# EG32M0x register map
Vendor: EGmicro Ltd.; Series: EG32M0x; File version: 1.0
CPU: CM0 r0p0, little endian, no MPU, no FPU, 3 interrupt priority bits
Registers are 32-bit, read-write, reset 0x0 unless marked. A register's access mark holds for its fields unless they carry their own. Offsets are from the block's base; [hi:lo] are bit positions; {n}, {i} and the like mark numbered series.

## HWDIV — HWDIV unit
Base 0x400203A0
0x00 DR
  [31:0] DIVDR — Dividend data
0x04 SR
  [31:0] DIVSR — Divisor data
0x08 QUO
  [31:0] DIVQUO — Quotient result
0x0C REM
  [31:0] DIVREM — Remainder result
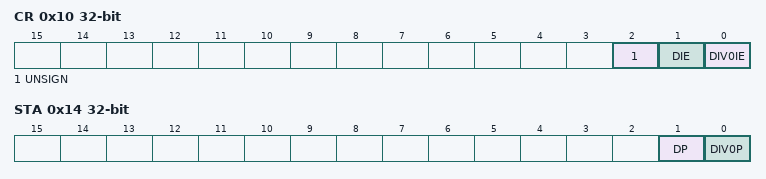
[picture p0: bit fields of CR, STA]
0x10 CR
  [2] UNSIGN — Operation symbol bit control
  [1] DIE — End of operation interrupt control bit
  [0] DIV0IE — Divisor is 0 interrupt control bit
0x14 STA
  [1] DP — End of operation flag bit
  [0] DIV0P — The divisor is 0

## POWER_MAN — POWER MANAGEMENT unit
Base 0x40020120
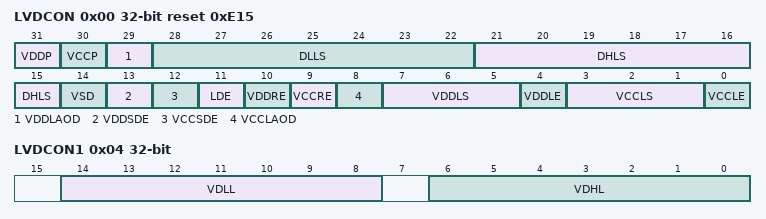
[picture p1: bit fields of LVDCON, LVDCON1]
0x00 LVDCON reset 0xE15
  [31] VDDP — When the VDD voltage is lower than the threshold, the PEND is triggered
  [30] VCCP — When the VCC voltage is lower than the threshold, the PEND is triggered
  [29] VDDLAOD — VDD_LVD Analog signal output is enabled
  [28:22] DLLS — Low level burr filter width for PMU_LVD_VDD signal The degree of
  [21:15] DHLS — High level burr filter width for PMU_LVD_VDD signal The degree of
  [14] VSD — VCC_LVD Indicates whether to wake up the CPU in interrupt mode The system clock must be synchronized first
  [13] VDDSDE — Mask the filtering processing of PMU_VDD_LVD signal
  [12] VCCSDE — Mask the filtering processing of PMU_VCC_LVD signal
  [11] LDE — LVD digital switch
  [10] VDDRE — The system reset function is enabled after the VDD threshold is triggered
  [9] VCCRE — The system reset function is enabled after the VCC threshold is triggered
  [8] VCCLAOD — VCC_LVD Analog signal output is enabled
  [7:5] VDDLS — VDD_LVD Voltage detection Setting
  [4] VDDLE — VDD_LVD analog switch
  [3:1] VCCLS — VCC_LVD Voltage detection Setting
  [0] VCCLE — VCC_LVD analog switch
0x04 LVDCON1
  [14:8] VDLL — Low level burr filter width for PMU_LVD_VCC signal The degree of
  [6:0] VDHL — High level burr filter width for PMU_LVD_VCC signal The degree of

## GPIOA — GPIOA unit
Base 0x400200A0
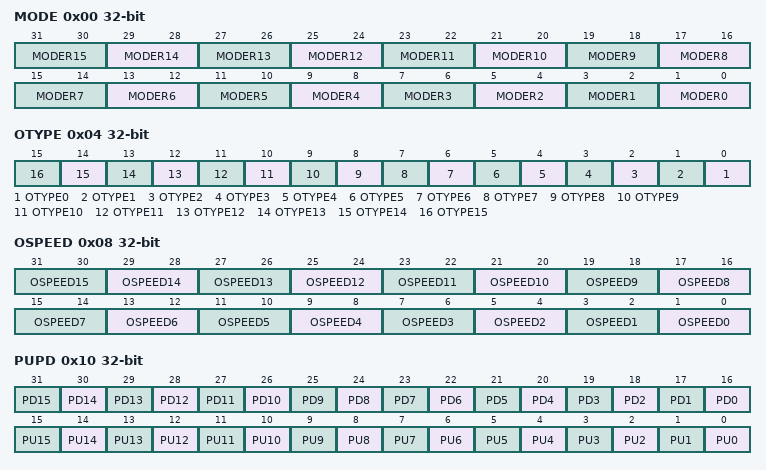
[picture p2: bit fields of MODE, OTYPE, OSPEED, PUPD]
0x00 MODE
  [2n+1:2n] MODER{n} (n=0..15) — The mode bit of GPIOA PIN{n}
0x04 OTYPE
  [n] OTYPE{n} (n=0..15) — The output type selection bit of GPIOA PIN{n}
0x08 OSPEED
  [2n+1:2n] OSPEED{n} (n=0..15) — The Speed gear selection bit of GPIOA PIN{n}
0x10 PUPD
  [n+16] PD{n} (n=0..15) — The drop-down enable bit of GPIOA PIN{n}
  [n] PU{n} (n=0..15) — The pull-up enable bit of GPIOA PIN{n}
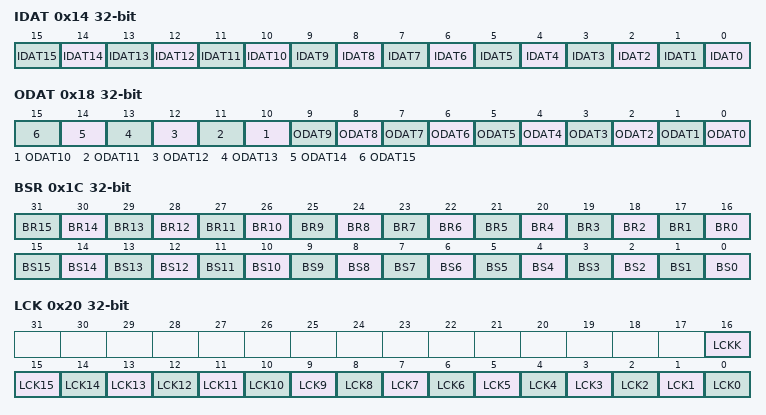
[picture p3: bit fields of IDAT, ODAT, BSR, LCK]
0x14 IDAT
  [n] IDAT{n} (n=0..15) — The Input data bit of GPIOA PIN{n}
0x18 ODAT
  [n] ODAT{n} (n=0..15) — The output data bit of GPIOA PIN{n}
0x1C BSR
  [n+16] BR{n} (n=0..15) — The Clear bit of GPIOA PIN{n}
  [n] BS{n} (n=0..15) — The setting bit of GPIOA PIN{n}
0x20 LCK
  [16] LCKK — The locking mechanism valid bit of GPIOA
  [n] LCK{n} (n=0..15) — The lock enable bit of GPIOA PIN{n}
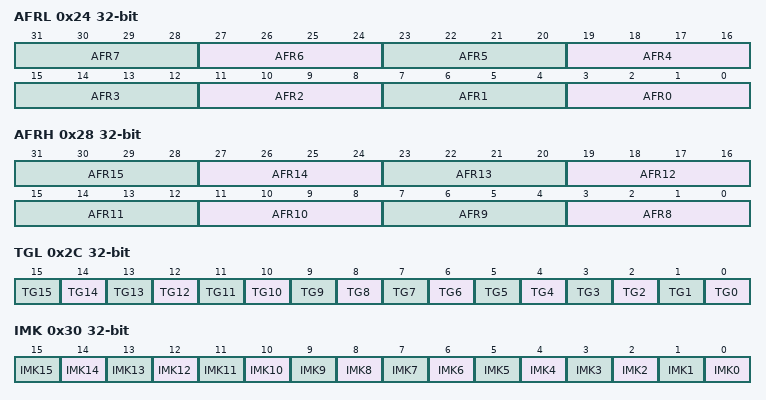
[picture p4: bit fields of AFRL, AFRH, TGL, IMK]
0x24 AFRL
  [4n+3:4n] AFR{n} (n=0..7) — GPIOA[{n}] multiplexed channel selection bit
0x28 AFRH
  [4n-29:4n-32] AFR{n} (n=8..15) — GPIOA[{n}] multiplexed channel selection bit
0x2C TGL
  [n] TG{n} (n=0..15) — The flip bit of GPIOA PIN{n}
0x30 IMK
  [n] IMK{n} (n=0..15) — The Interrupt enable bit of GPIOA PIN{n}
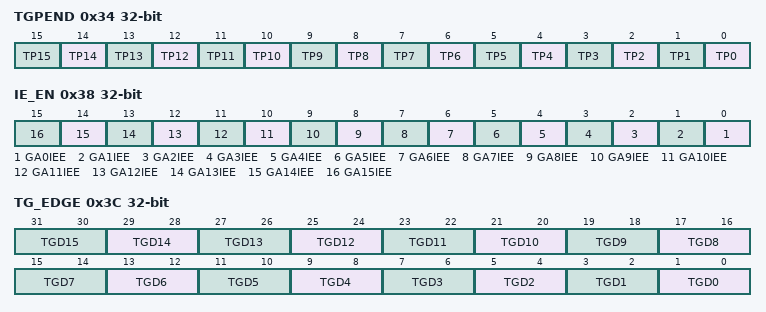
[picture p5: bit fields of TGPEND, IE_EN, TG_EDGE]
0x34 TGPEND
  [n] TP{n} (n=0..15) — The input edge detection flag bit of GPIOA PIN{n}
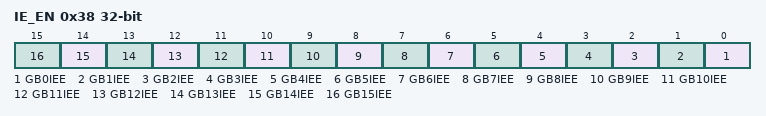
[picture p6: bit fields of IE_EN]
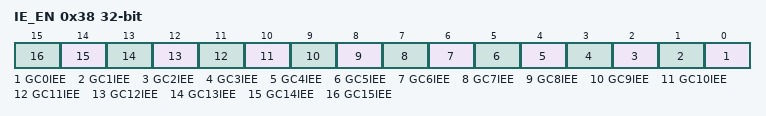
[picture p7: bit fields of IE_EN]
0x38 IE_EN
  [n] GA{n}IEE (n=0..15) — The input force enable bit of GPIOA PIN{n}
0x3C TG_EDGE
  [2n+1:2n] TGD{n} (n=0..15) — Detection control bit of the input edge of GPIOA PIN{n}

## GPIOB — GPIOB unit
Base 0x400200E0
Registers as GPIOA (with GPIOA read as GPIOB); these are added or differ:
0x38 IE_EN
  [n] GB{n}IEE (n=0..15) — The input force enable bit of GPIOB PIN{n}

## GPIOC — GPIOC unit
Base 0x400201B0
Registers as GPIOA (with GPIOA read as GPIOC); these are added or differ:
0x38 IE_EN
  [n] GC{n}IEE (n=0..15) — The input force enable bit of GPIOC PIN{n}
